# ATSAMD21E16L register map
Vendor: Atmel Corporation; Series: SAMD21; File version: D
Atmel ATSAMD21E16L device: Cortex-M0+ Microcontroller with 64KB Flash, 8KB SRAM, QFN32_LIGHTING-pin package (refer to http://www.atmel.com/devices/SAMD21E16L.aspx for more)
CPU: CM0+ r0p1, little endian, no MPU, no FPU, VTOR, 2 interrupt priority bits
Registers are 32-bit, read-write, reset 0x0 unless marked. A register's access mark holds for its fields unless they carry their own. Offsets are from the block's base; lines under a group give offsets from that group; [hi:lo] are bit positions; {n}, {i} and the like mark numbered series; 'fields as' and 'values as' point back to an identical list; <NAME> marks a mode.

## Memory map
0x40000000 PAC0 size 0x8 — Peripheral Access Controller 0
0x40000400 PM size 0x80 — Power Manager
0x40000800 SYSCTRL size 0x80 — System Control
0x40000C00 GCLK size 0x10 — Generic Clock Generator
0x40001000 WDT size 0x10 — Watchdog Timer
0x40001400 RTC size 0x40 — Real-Time Counter
0x40001800 EIC size 0x40 — External Interrupt Controller
0x41000000 PAC1 size 0x8 — Peripheral Access Controller 1
0x41002000 DSU size 0x2000 — Device Service Unit
0x41004000 NVMCTRL size 0x80 — Non-Volatile Memory Controller
0x41004400 PORT size 0x200 — Port Module
0x41004800 DMAC size 0x80 — Direct Memory Access Controller
0x41006000 MTB size 0x1000 — Cortex-M0+ Micro-Trace Buffer
0x41007000 HMATRIX size 0x400 — HSB Matrix
0x42000000 PAC2 size 0x8 — Peripheral Access Controller 2
0x42000400 EVSYS size 0x80 — Event System Interface
0x42000800 SERCOM0 size 0x40 — Serial Communication Interface 0
0x42000C00 SERCOM1 size 0x40 — Serial Communication Interface 1
0x42001000 SERCOM2 size 0x40 — Serial Communication Interface 2
0x42001400 SERCOM3 size 0x40 — Serial Communication Interface 3
0x42002000 TCC0 size 0x90 — Timer Counter Control 0
0x42002400 TCC1 size 0x90 — Timer Counter Control 1
0x42002800 TCC2 size 0x90 — Timer Counter Control 2
0x42002C00 TC3 size 0x40 — Basic Timer Counter 3
0x42003000 TC4 size 0x40 — Basic Timer Counter 4
0x42003400 TC5 size 0x40 — Basic Timer Counter 5
0x42004000 ADC size 0x80 — Analog Digital Converter
0x42004400 AC size 0x40 — Analog Comparators
0x42004800 DAC size 0x10 — Digital Analog Converter
0x42005400 AC1 size 0x40 — Analog Comparators 1
0x60000000 PORT_IOBUS size 0x200 — Port Module (IOBUS)

## Interrupts
0 PM_INTREQ (PM)
1 SYSCTRL_INTREQ (SYSCTRL)
2 WDT_INTREQ (WDT)
3 RTC_INTREQ (RTC)
4 EIC_INTREQ (EIC)
5 NVMCTRL_INTREQ (NVMCTRL)
6 DMAC_INTREQ (DMAC)
8 EVSYS_INTREQ (EVSYS)
9 SERCOM0_INTREQ (SERCOM0)
10 SERCOM1_INTREQ (SERCOM1)
11 SERCOM2_INTREQ (SERCOM2)
12 SERCOM3_INTREQ (SERCOM3)
15 TCC0_INTREQ (TCC0)
16 TCC1_INTREQ (TCC1)
17 TCC2_INTREQ (TCC2)
18 TC3_INTREQ (TC3)
19 TC4_INTREQ (TC4)
20 TC5_INTREQ (TC5)
23 ADC_INTREQ (ADC)
24 AC_INTREQ (AC)
25 DAC_INTREQ (DAC)
28 AC1_INTREQ (AC1)

## AC — Analog Comparators
Base 0x42004400; register names take the prefix AC_
Same registers: AC1 0x42005400
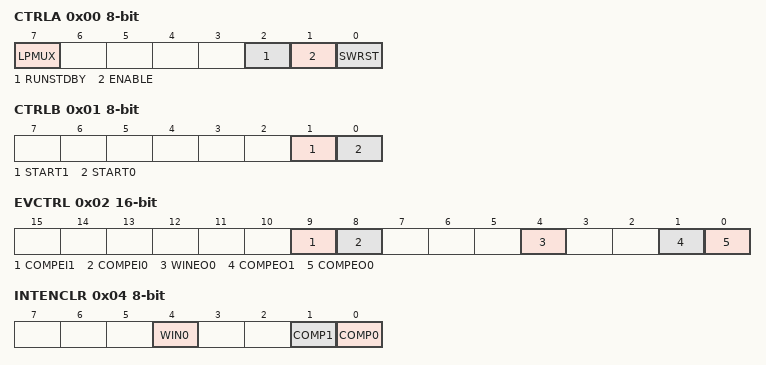
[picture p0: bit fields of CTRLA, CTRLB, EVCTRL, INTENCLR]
0x00 CTRLA 8-bit — Control A
  [7] LPMUX — Low-Power Mux
  [2] RUNSTDBY — Run in Standby
  [1] ENABLE
  [0] SWRST wo — Software Reset
0x01 CTRLB 8-bit wo — Control B
  [1] START1 — Comparator 1 Start Comparison
  [0] START0 — Comparator 0 Start Comparison
0x02 EVCTRL 16-bit — Event Control
  [9] COMPEI1 — Comparator 1 Event Input
  [8] COMPEI0 — Comparator 0 Event Input
  [4] WINEO0 — Window 0 Event Output Enable
  [1] COMPEO1 — Comparator 1 Event Output Enable
  [0] COMPEO0 — Comparator 0 Event Output Enable
0x04 INTENCLR 8-bit — Interrupt Enable Clear
  [4] WIN0 — Window 0 Interrupt Enable
  [1] COMP1 — Comparator 1 Interrupt Enable
  [0] COMP0 — Comparator 0 Interrupt Enable
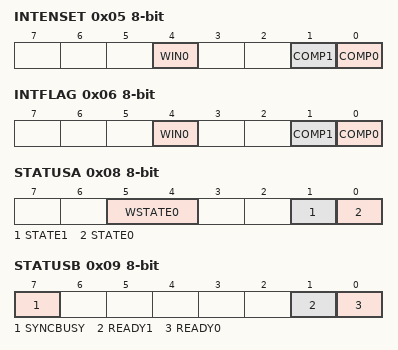
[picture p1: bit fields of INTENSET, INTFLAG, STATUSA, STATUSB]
0x05 INTENSET 8-bit — Interrupt Enable Set
  fields as INTENCLR
0x06 INTFLAG 8-bit — Interrupt Flag Status and Clear
  [4] WIN0 — Window 0
  [1] COMP1 — Comparator 1
  [0] COMP0 — Comparator 0
0x08 STATUSA 8-bit ro
  [5:4] WSTATE0 — Window 0 Current State
    0=ABOVE (Signal is above window); 1=INSIDE (Signal is inside window); 2=BELOW (Signal is below window)
  [1] STATE1 — Comparator 1 Current State
  [0] STATE0 — Comparator 0 Current State
0x09 STATUSB 8-bit ro
  [7] SYNCBUSY — Synchronization Busy
  [1] READY1 — Comparator 1 Ready
  [0] READY0 — Comparator 0 Ready
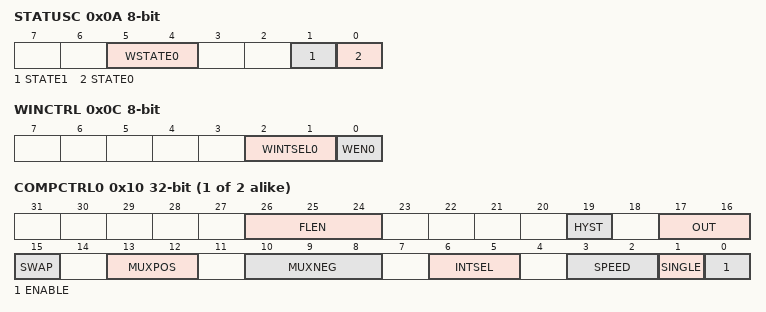
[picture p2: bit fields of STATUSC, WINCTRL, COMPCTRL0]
0x0A STATUSC 8-bit ro
  fields as STATUSA
0x0C WINCTRL 8-bit — Window Control
  [2:1] WINTSEL0 — Window 0 Interrupt Selection
    0=ABOVE (Interrupt on signal above window); 1=INSIDE (Interrupt on signal inside window); 2=BELOW (Interrupt on signal below window); 3=OUTSIDE (Interrupt on signal outside window)
  [0] WEN0 — Window 0 Mode Enable
{0x10+4i} COMPCTRL{i} (i=0..1) — Comparator Control n
  [26:24] FLEN — Filter Length
    0=OFF (No filtering); 1=MAJ3 (3-bit majority function (2 of 3)); 2=MAJ5 (5-bit majority function (3 of 5))
  [19] HYST — Hysteresis Enable
  [17:16] OUT — Output
    0=OFF (The output of COMPn is not routed to the COMPn I/O port); 1=ASYNC (The asynchronous output of COMPn is routed to the COMPn I/O port); 2=SYNC (The synchronous output (including filtering) of COMPn is routed to the COMPn I/O port)
  [15] SWAP — Swap Inputs and Invert
  [13:12] MUXPOS — Positive Input Mux Selection
    {v}=PIN{v} (I/O pin {v}) (v=0..3)
  [10:8] MUXNEG — Negative Input Mux Selection
    {v}=PIN{v} (I/O pin {v}) (v=0..3); 4=GND (Ground); 5=VSCALE (VDD scaler); 6=BANDGAP (Internal bandgap voltage); 7=DAC (DAC output)
  [6:5] INTSEL — Interrupt Selection
    0=TOGGLE (Interrupt on comparator output toggle); 1=RISING (Interrupt on comparator output rising); 2=FALLING (Interrupt on comparator output falling); 3=EOC (Interrupt on end of comparison (single-shot mode only))
  [3:2] SPEED — Speed Selection
    0=LOW (Low speed); 1=HIGH (High speed)
  [1] SINGLE — Single-Shot Mode
  [0] ENABLE
{0x20+i} SCALER{i} (i=0..1) 8-bit — Scaler n
  [5:0] VALUE — Scaler Value

## Licence text in the file
============================================================================ Atmel Microcontroller Software Support ============================================================================ Copyright (c) 2016 Atmel Corporation, a wholly owned subsidiary of Microchip Technology Inc. . Licensed under the Apache License, Version 2.0 (the "License"); you may not use this file except in compliance with the License. You may obtain a copy of the Licence at http://www.apache.org/licenses/LICENSE-2.0 . Unless required by applicable law or agreed to in writing, software distributed under the License is distributed on an "AS IS" BASIS, WITHOUT WARRANTIES OR CONDITIONS OF ANY KIND, either express or implied. See the License for the specific language governing permissions and limitations under the License. ============================================================================
